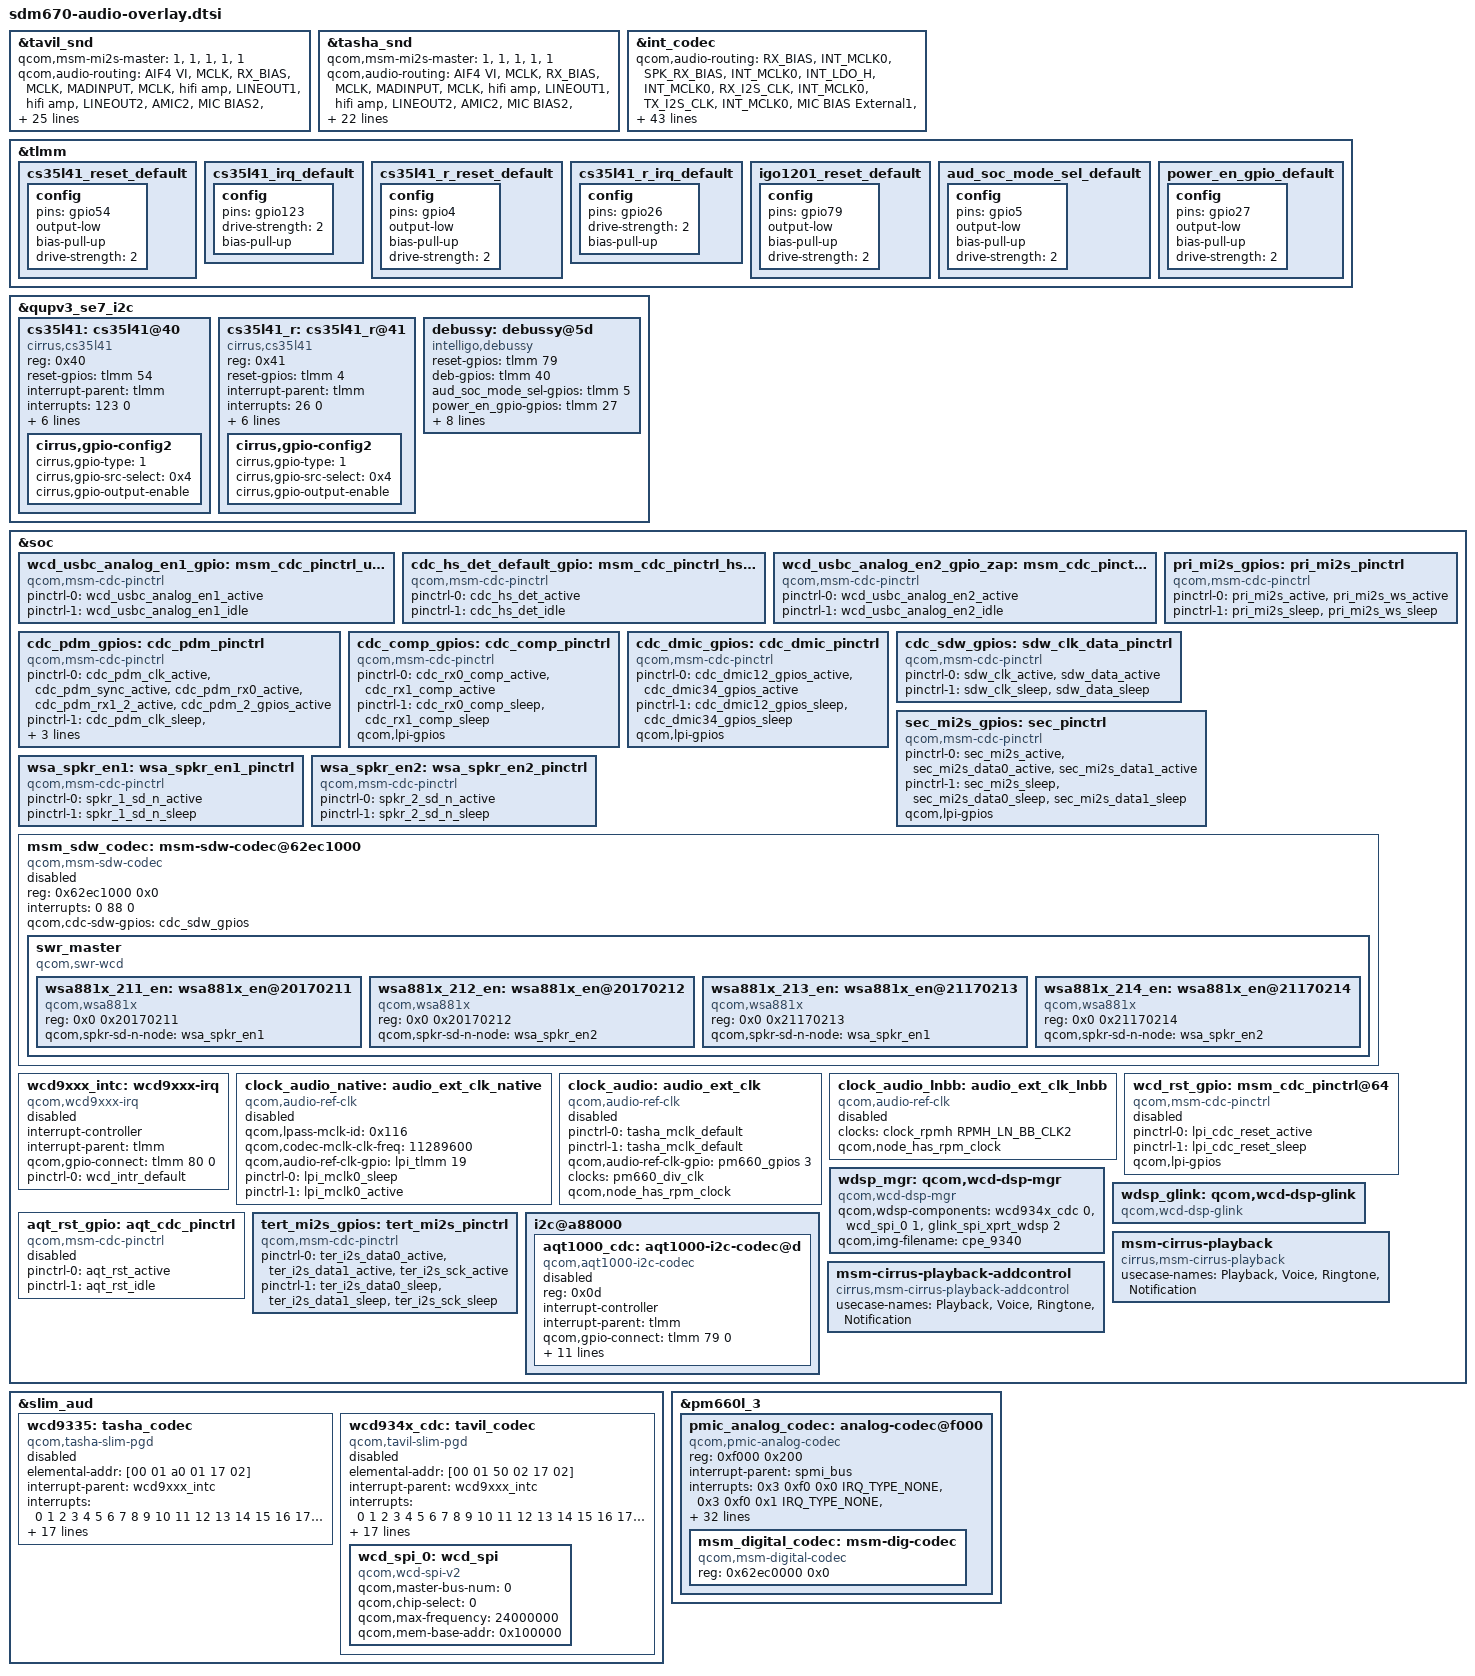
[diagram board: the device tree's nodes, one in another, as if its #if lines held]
/*
 * Copyright (c) 2017-2018, The Linux Foundation. All rights reserved.
 *
 * This program is free software; you can redistribute it and/or modify
 * it under the terms of the GNU General Public License version 2 and
 * only version 2 as published by the Free Software Foundation.
 *
 * This program is distributed in the hope that it will be useful,
 * but WITHOUT ANY WARRANTY; without even the implied warranty of
 * MERCHANTABILITY or FITNESS FOR A PARTICULAR PURPOSE.  See the
 * GNU General Public License for more details.
 */
#include "sdm670-wcd.dtsi"
#include "sdm670-wsa881x.dtsi"
#include "sdm670-lpi.dtsi"
#include <dt-bindings/clock/qcom,audio-ext-clk.h>
#include <generated/autoconf.h>

&tavil_snd {
	qcom,msm-mi2s-master = <1>, <1>, <1>, <1>, <1>;
	qcom,audio-routing =
		"AIF4 VI", "MCLK",
		"RX_BIAS", "MCLK",
		"MADINPUT", "MCLK",
		"hifi amp", "LINEOUT1",
		"hifi amp", "LINEOUT2",
		"AMIC2", "MIC BIAS2",
		"MIC BIAS2", "Headset Mic",
		"AMIC3", "MIC BIAS2",
		"MIC BIAS2", "ANCRight Headset Mic",
		"AMIC4", "MIC BIAS2",
		"MIC BIAS2", "ANCLeft Headset Mic",
		"AMIC5", "MIC BIAS3",
		"MIC BIAS3", "Handset Mic",
		"DMIC0", "MIC BIAS1",
		"MIC BIAS1", "Digital Mic0",
		"DMIC1", "MIC BIAS1",
		"MIC BIAS1", "Digital Mic1",
		"DMIC2", "MIC BIAS3",
		"MIC BIAS3", "Digital Mic2",
		"DMIC3", "MIC BIAS3",
		"MIC BIAS3", "Digital Mic3",
		"DMIC4", "MIC BIAS4",
		"MIC BIAS4", "Digital Mic4",
		"DMIC5", "MIC BIAS4",
		"MIC BIAS4", "Digital Mic5",
		"SpkrLeft IN", "SPK1 OUT",
		"SpkrRight IN", "SPK2 OUT";

	qcom,msm-mbhc-hphl-swh = <1>;
	qcom,msm-mbhc-gnd-swh = <1>;
	qcom,hph-en0-gpio = <&tavil_hph_en0>;
	qcom,hph-en1-gpio = <&tavil_hph_en1>;
	qcom,msm-mclk-freq = <9600000>;
	asoc-codec = <&stub_codec>, <&ext_disp_audio_codec>;
	asoc-codec-names = "msm-stub-codec.1", "msm-ext-disp-audio-codec-rx";
	qcom,wsa-max-devs = <2>;
	qcom,wsa-devs = <&wsa881x_0211>, <&wsa881x_0212>,
		<&wsa881x_0213>, <&wsa881x_0214>;
	qcom,wsa-aux-dev-prefix = "SpkrLeft", "SpkrRight",
		"SpkrLeft", "SpkrRight";
};

&tasha_snd {
	qcom,msm-mi2s-master = <1>, <1>, <1>, <1>, <1>;
	qcom,audio-routing =
		"AIF4 VI", "MCLK",
		"RX_BIAS", "MCLK",
		"MADINPUT", "MCLK",
		"hifi amp", "LINEOUT1",
		"hifi amp", "LINEOUT2",
		"AMIC2", "MIC BIAS2",
		"MIC BIAS2", "Headset Mic",
		"AMIC3", "MIC BIAS2",
		"MIC BIAS2", "ANCRight Headset Mic",
		"AMIC4", "MIC BIAS2",
		"MIC BIAS2", "ANCLeft Headset Mic",
		"AMIC5", "MIC BIAS3",
		"MIC BIAS3", "Handset Mic",
		"DMIC0", "MIC BIAS1",
		"MIC BIAS1", "Digital Mic0",
		"DMIC1", "MIC BIAS1",
		"MIC BIAS1", "Digital Mic1",
		"DMIC2", "MIC BIAS3",
		"MIC BIAS3", "Digital Mic2",
		"DMIC3", "MIC BIAS3",
		"MIC BIAS3", "Digital Mic3",
		"DMIC4", "MIC BIAS4",
		"MIC BIAS4", "Digital Mic4",
		"DMIC5", "MIC BIAS4",
		"MIC BIAS4", "Digital Mic5",
		"SpkrLeft IN", "SPK1 OUT",
		"SpkrRight IN", "SPK2 OUT";

	qcom,msm-mbhc-hphl-swh = <0>;
	qcom,msm-mbhc-gnd-swh = <0>;
	qcom,msm-mclk-freq = <9600000>;
	asoc-codec = <&stub_codec>;
	asoc-codec-names = "msm-stub-codec.1";
	qcom,wsa-max-devs = <2>;
	qcom,wsa-devs = <&wsa881x_211>, <&wsa881x_212>,
		<&wsa881x_213>, <&wsa881x_214>;
	qcom,wsa-aux-dev-prefix = "SpkrLeft", "SpkrRight",
		"SpkrLeft", "SpkrRight";
};

&int_codec {
	qcom,audio-routing =
		"RX_BIAS", "INT_MCLK0",
		"SPK_RX_BIAS", "INT_MCLK0",
		"INT_LDO_H", "INT_MCLK0",
		"RX_I2S_CLK", "INT_MCLK0",
		"TX_I2S_CLK", "INT_MCLK0",
#if defined(CONFIG_PRODUCT_ZAP)
		"MIC BIAS External1", "Handset Mic",
		"MIC BIAS External2", "Headset Mic",
		"MIC BIAS External3", "Secondary Mic",
		"AMIC1", "MIC BIAS External",
		"AMIC2", "MIC BIAS External2",
		"AMIC3", "MIC BIAS External3",
#else
		"MIC BIAS External", "Handset Mic",
		"MIC BIAS External2", "Headset Mic",
		"MIC BIAS External", "Secondary Mic",
		"AMIC1", "MIC BIAS External",
		"AMIC2", "MIC BIAS External2",
		"AMIC3", "MIC BIAS External",
		"DMIC1", "MIC BIAS External",
		"MIC BIAS External", "Digital Mic1",
		"DMIC2", "MIC BIAS External",
		"MIC BIAS External", "Digital Mic2",
		"DMIC3", "MIC BIAS External",
		"MIC BIAS External", "Digital Mic3",
		"DMIC4", "MIC BIAS External",
		"MIC BIAS External", "Digital Mic4",
		"MICBIAS_REGULATOR", "VDDA18_L10_REGULATOR",
		"VDDA18_L10_REGULATOR", "VDD_L1_REGULATOR",
#endif
		"SpkrLeft IN", "SPK1 OUT",
		"SpkrRight IN", "SPK2 OUT",
		"PDM_IN_RX1", "PDM_OUT_RX1",
		"PDM_IN_RX2", "PDM_OUT_RX2",
		"PDM_IN_RX3", "PDM_OUT_RX3",
		"ADC1_IN", "ADC1_OUT",
		"ADC2_IN", "ADC2_OUT",
		"ADC3_IN", "ADC3_OUT";
	qcom,msm-mi2s-master = <1>, <1>, <1>, <1>, <1>;
	qcom,msm-mclk-freq = <9600000>;
	qcom,msm-mbhc-hphl-swh = <1>;
	qcom,msm-mbhc-gnd-swh = <1>;
	qcom,msm-micbias2-ext-cap;
#if defined(CONFIG_PRODUCT_KUNLUN2)
        qcom,msm-micbias1-ext-cap;
#endif
	qcom,msm-hs-micbias-type = "external";
	/* huaqin add for JD2019-123 by xudayi at 2018/08/3 start */
      //qcom,sec-mi2s-gpios = <&sec_mi2s_gpios>;
	/* huaqin add for JD2019-123 by xudayi at 2018/08/3 end */

#if defined(CONFIG_PRODUCT_ZAP)
	qcom,msm-mbhc-usbc-audio-supported = <1>;
	qcom,usbc-analog-force_detect_gpio = <&cdc_hs_det_default_gpio>;
	qcom,usbc-analog-en1-gpio = <&wcd_usbc_analog_en1_gpio>;
	qcom,usbc-analog-en2-gpio = <&wcd_usbc_analog_en2_gpio_zap>;
	/*qcom,usbc-analog-en2-gpio = <&tlmm 50 0>;
	pinctrl-names = "aud_active", "aud_sleep";
	pinctrl-0 = <&wcd_usbc_analog_en2_active>;
	pinctrl-1 = <&wcd_usbc_analog_en2_idle>;*/
#endif

	qcom,cdc-pdm-gpios = <&cdc_pdm_gpios>;
	qcom,cdc-comp-gpios = <&cdc_comp_gpios>;
	qcom,cdc-dmic-gpios = <&cdc_dmic_gpios>;
#if defined(CONFIG_PRODUCT_ZAP)
	qcom,pri-mi2s-gpios = <&pri_mi2s_gpios>;
	qcom,sec-mi2s-gpios = <&sec_mi2s_gpios>;
	qcom,tert-mi2s-gpios = <&tert_mi2s_gpios>;
#endif

	asoc-codec = <&stub_codec>, <&msm_digital_codec>,
		     <&pmic_analog_codec>, <&msm_sdw_codec>,
		     /* huaqin add for JD2019-123 by xudayi at 2018/08/31 start */
		     <&ext_disp_audio_codec>,
#if defined(CONFIG_PRODUCT_ZAP)
		     <&cs35l41>, <&cs35l41_r>, <&debussy>;
#else
		     <&cs35l41>, <&cs35l41_r>;
#endif
		     /* huaqin add for JD2019-123 by xudayi at 2018/08/31 end */
	asoc-codec-names = "msm-stub-codec.1", "msm-dig-codec",
			   "analog-codec", "msm_sdw_codec",
			   /* huaqin add for JD2019-123 by xudayi at 2018/08/31 start */
			   "msm-ext-disp-audio-codec-rx",
#if defined(CONFIG_PRODUCT_ZAP)
		     "cs35l41", "cs35l41_r", "debussy";
#else
			   "cs35l41", "cs35l41_r";
#endif
			   /* huaqin add for JD2019-123 by xudayi at 2018/08/31 end */
	/* huaqin add for JD2019-111 by xudayi at 2018/08/30 start */
	qcom,wsa-disable;
	qcom,wsa-max-devs = <0>;
	/* huaqin add for JD2019-111 by xudayi at 2018/08/30 end */
	qcom,wsa-devs = <&wsa881x_211_en>, <&wsa881x_212_en>,
			<&wsa881x_213_en>, <&wsa881x_214_en>;
	qcom,wsa-aux-dev-prefix = "SpkrLeft", "SpkrRight",
				  "SpkrLeft", "SpkrRight";
};


/* huaqin add for JD2019-123 by xudayi at 2018/08/31 start */
&tlmm {
	cs35l41_reset_default: cs35l41_reset_default {
		config {
#if defined(CONFIG_PRODUCT_ZAP)
			pins = "gpio54";
#else
			pins = "gpio93";
#endif
			output-low;
			bias-pull-up;
			drive-strength = <2>;
		};
	};

	/* huaqin add for JD2019-303 by xudayi at 2018/09/12 start */
	cs35l41_irq_default: cs35l41_irq_default {
		config {
#if defined(CONFIG_PRODUCT_ZAP)
			pins = "gpio123";
#else
			pins = "gpio26";
#endif
			drive-strength = <2>;
			bias-pull-up;
		};
	};
	/* huaqin add for JD2019-303 by xudayi at 2018/09/12 end */

	cs35l41_r_reset_default: cs35l41_r_reset_default {
		config {
#if defined(CONFIG_PRODUCT_ZAP)
			pins = "gpio4";
#else
			pins = "gpio50";
#endif
			output-low;
			bias-pull-up;
			drive-strength = <2>;
		};
	};
	/* huaqin add for JD2019-303 by xudayi at 2018/09/12 start */
	cs35l41_r_irq_default: cs35l41_r_irq_default {
		config {
#if defined(CONFIG_PRODUCT_ZAP)
			pins = "gpio26";
#else
			pins = "gpio49";
#endif
			drive-strength = <2>;
			bias-pull-up;
		};
	};
	/* huaqin add for JD2019-303 by xudayi at 2018/09/12 end */
#if defined(CONFIG_PRODUCT_ZAP)
	igo1201_reset_default: igo1201_reset_default {
		config {
			pins = "gpio79";
			output-low;
			bias-pull-up;
			drive-strength = <2>;
		};
	};

	aud_soc_mode_sel_default: aud_soc_mode_sel_default {
		config {
			pins = "gpio5";
			output-low;
			bias-pull-up;
			drive-strength = <2>;
		};
	};

	power_en_gpio_default: power_en_gpio_default {
		config {
			pins = "gpio27";
			output-low;
			bias-pull-up;
			drive-strength = <2>;
		};
	};
#endif
};

#if defined(CONFIG_PRODUCT_ZAP)
&qupv3_se7_i2c {
        status = "okay";

	/* Speaker Amp */
	cs35l41:cs35l41@40 {
		status = "okay";
		compatible = "cirrus,cs35l41";
		reg = <0x40>;

		reset-gpios = <&tlmm 54 0>;
		interrupt-parent = <&tlmm>;
		interrupts = <123 0>;
		interrupt-names = "amp_l_irq";

		cirrus,right-channel-amp; /* Set Speaker Amp as default Right channel */
		cirrus,boost-peak-milliamp = <4500>;
		cirrus,boost-ind-nanohenry = <1000>;
		cirrus,boost-cap-microfarad = <15>;
		cirrus,asp-sdout-hiz = <0x3>;

		pinctrl-names = "reset";
		pinctrl-0 = <&cs35l41_reset_default>;
		cirrus,gpio-config2 {
			cirrus,gpio-type = <1>; /* 0 indicate gpio, 1 indicate interrupt */
			cirrus,gpio-src-select = <0x4>;
			cirrus,gpio-output-enable;
		};
 	};

	/* Receiver Amp */
	cs35l41_r:cs35l41_r@41 {
		status = "okay";
		compatible = "cirrus,cs35l41";
		reg = <0x41>;

		reset-gpios = <&tlmm 4 0>;
		interrupt-parent = <&tlmm>;
		interrupts = <26 0>;
		interrupt-names = "amp_r_irq";

		cirrus,boost-peak-milliamp = <4500>;
		cirrus,boost-ind-nanohenry = <1000>;
		cirrus,boost-cap-microfarad = <15>;
		cirrus,asp-sdout-hiz = <0x3>;
		cirrus,dsp-recovery;
		pinctrl-names = "reset";
		pinctrl-0 = <&cs35l41_r_reset_default>;
		cirrus,gpio-config2 {
			cirrus,gpio-type = <1>; /* 0 indicate gpio, 1 indicate interrupt */
			cirrus,gpio-src-select = <0x4>;
			cirrus,gpio-output-enable;
		};
	};

	debussy:debussy@5d {
			status = "okay";
			compatible = "intelligo,debussy";
			reset-gpios = <&tlmm 79 0>;
			deb-gpios = <&tlmm 40 0>;
			aud_soc_mode_sel-gpios = <&tlmm 5 0>;
			power_en_gpio-gpios = <&tlmm 27 0>;
			reg = <0x5d>;
			interrupt-parent = <&tlmm>;
			interrupts = <40 IRQ_TYPE_EDGE_RISING>;
			debounce = <5>;
			clock-names = "igo_mclk";
			clocks = <&clock_rpmh RPMH_LN_BB_CLK2>;

			pinctrl-names = "reset", "aud_soc_mode_sel", "power_en_gpio";
			pinctrl-0 = <&igo1201_reset_default>;
			pinctrl-1 = <&aud_soc_mode_sel_default>;
			pinctrl-2 = <&power_en_gpio_default>;
	};
};
#else
&qupv3_se3_i2c {
        status = "okay";

	/* Speaker Amp */
	cs35l41:cs35l41@43 {
		status = "okay";
		compatible = "cirrus,cs35l41";
		reg = <0x43>;

		reset-gpios = <&tlmm 93 0>;
		interrupt-parent = <&tlmm>;
		interrupts = <26 0>;
		interrupt-names = "amp_l_irq";

		cirrus,right-channel-amp; /* Set Speaker Amp as default Right channel */
		cirrus,boost-peak-milliamp = <4500>;
		cirrus,boost-ind-nanohenry = <1000>;
		cirrus,boost-cap-microfarad = <15>;
		cirrus,asp-sdout-hiz = <0x3>;

		pinctrl-names = "reset";
		pinctrl-0 = <&cs35l41_reset_default>;
		cirrus,gpio-config2 {
			cirrus,gpio-type = <1>; /* 0 indicate gpio, 1 indicate interrupt */
			cirrus,gpio-src-select = <0x4>;
			cirrus,gpio-output-enable;
		};
	};

	/* Receiver Amp */
	cs35l41_r:cs35l41_r@40 {
		status = "okay";
		compatible = "cirrus,cs35l41";
		reg = <0x40>;

		reset-gpios = <&tlmm 50 0>;
		interrupt-parent = <&tlmm>;
		interrupts = <49 0>;
		interrupt-names = "amp_r_irq";

		cirrus,boost-peak-milliamp = <4500>;
		cirrus,boost-ind-nanohenry = <1000>;
		cirrus,boost-cap-microfarad = <15>;
		cirrus,asp-sdout-hiz = <0x3>;

		pinctrl-names = "reset";
		pinctrl-0 = <&cs35l41_r_reset_default>;
		cirrus,gpio-config2 {
			cirrus,gpio-type = <1>; /* 0 indicate gpio, 1 indicate interrupt */
			cirrus,gpio-src-select = <0x4>;
			cirrus,gpio-output-enable;
		};
	};
};
#endif

/* huaqin add for JD2019-123 by xudayi at 2018/08/31 end */
&soc {
	wcd_usbc_analog_en1_gpio: msm_cdc_pinctrl_usbc_audio_en1 {
		compatible = "qcom,msm-cdc-pinctrl";
		pinctrl-names = "aud_active", "aud_sleep";
		pinctrl-0 = <&wcd_usbc_analog_en1_active>;
		pinctrl-1 = <&wcd_usbc_analog_en1_idle>;
	};
#if defined(CONFIG_PRODUCT_ZAP)
	cdc_hs_det_default_gpio: msm_cdc_pinctrl_hs_det_default {
		compatible = "qcom,msm-cdc-pinctrl";
		pinctrl-names = "aud_active", "aud_sleep";
		pinctrl-0 = <&cdc_hs_det_active>;
		pinctrl-1 = <&cdc_hs_det_idle>;
	};

	wcd_usbc_analog_en2_gpio_zap: msm_cdc_pinctrl_usbc_audio_en2 {
		compatible = "qcom,msm-cdc-pinctrl";
		pinctrl-names = "aud_active", "aud_sleep";
		pinctrl-0 = <&wcd_usbc_analog_en2_active>;
		pinctrl-1 = <&wcd_usbc_analog_en2_idle>;
	};

	pri_mi2s_gpios: pri_mi2s_pinctrl {
		status = "ok";
		compatible = "qcom,msm-cdc-pinctrl";
		pinctrl-names = "aud_active", "aud_sleep";
		pinctrl-0 = <&pri_mi2s_active &pri_mi2s_ws_active>;
		pinctrl-1 = <&pri_mi2s_sleep &pri_mi2s_ws_sleep>;
	};
#endif
	cdc_pdm_gpios: cdc_pdm_pinctrl {
		compatible = "qcom,msm-cdc-pinctrl";
		pinctrl-names = "aud_active", "aud_sleep";
		pinctrl-0 = <&cdc_pdm_clk_active &cdc_pdm_sync_active
			     &cdc_pdm_rx0_active &cdc_pdm_rx1_2_active
			     &cdc_pdm_2_gpios_active>;
		pinctrl-1 = <&cdc_pdm_clk_sleep &cdc_pdm_sync_sleep
			     &cdc_pdm_rx0_sleep &cdc_pdm_rx1_2_sleep
			     &cdc_pdm_2_gpios_sleep>;
		qcom,lpi-gpios;
	};

	cdc_comp_gpios: cdc_comp_pinctrl {
		compatible = "qcom,msm-cdc-pinctrl";
		pinctrl-names = "aud_active", "aud_sleep";
		pinctrl-0 = <&cdc_rx0_comp_active &cdc_rx1_comp_active>;
		pinctrl-1 = <&cdc_rx0_comp_sleep &cdc_rx1_comp_sleep>;
		qcom,lpi-gpios;
	};

	cdc_dmic_gpios: cdc_dmic_pinctrl {
		compatible = "qcom,msm-cdc-pinctrl";
		pinctrl-names = "aud_active", "aud_sleep";
		pinctrl-0 = <&cdc_dmic12_gpios_active
			     &cdc_dmic34_gpios_active>;
		pinctrl-1 = <&cdc_dmic12_gpios_sleep
			     &cdc_dmic34_gpios_sleep>;
		qcom,lpi-gpios;
	};

	cdc_sdw_gpios: sdw_clk_data_pinctrl {
		compatible = "qcom,msm-cdc-pinctrl";
#ifdef CONFIG_PRODUCT_JD2019
		pinctrl-names = "aud_active", "aud_sleep";
		pinctrl-0 = <&sdw_clk_active &sdw_data_active>;
		pinctrl-1 = <&sdw_clk_sleep &sdw_data_sleep>;
#endif
	};

	/* huaqin add for JD2019-123 by xudayi at 2018/08/3 start */
	sec_mi2s_gpios: sec_pinctrl {
		compatible = "qcom,msm-cdc-pinctrl";
		pinctrl-names = "aud_active", "aud_sleep";
		pinctrl-0 = <&sec_mi2s_active &sec_mi2s_data0_active
			&sec_mi2s_data1_active>;
		pinctrl-1 = <&sec_mi2s_sleep &sec_mi2s_data0_sleep
			&sec_mi2s_data1_sleep>;
		qcom,lpi-gpios;
	};
	/* huaqin add for JD2019-123 by xudayi at 2018/08/3 end */

	wsa_spkr_en1: wsa_spkr_en1_pinctrl {
		compatible = "qcom,msm-cdc-pinctrl";
#ifdef CONFIG_PRODUCT_JD2019
		pinctrl-names = "aud_active", "aud_sleep";
		pinctrl-0 = <&spkr_1_sd_n_active>;
		pinctrl-1 = <&spkr_1_sd_n_sleep>;
#endif
	};

	wsa_spkr_en2: wsa_spkr_en2_pinctrl {
		compatible = "qcom,msm-cdc-pinctrl";
#ifdef CONFIG_PRODUCT_JD2019
		pinctrl-names = "aud_active", "aud_sleep";
		pinctrl-0 = <&spkr_2_sd_n_active>;
		pinctrl-1 = <&spkr_2_sd_n_sleep>;
#endif
	};

	msm_sdw_codec: msm-sdw-codec@62ec1000 {
		status = "disabled";
		compatible = "qcom,msm-sdw-codec";
		reg = <0x62ec1000 0x0>;
		interrupts = <0 88 0>;
		interrupt-names = "swr_master_irq";
		qcom,cdc-sdw-gpios = <&cdc_sdw_gpios>;

		swr_master {
			compatible = "qcom,swr-wcd";
			#address-cells = <2>;
			#size-cells = <0>;

			wsa881x_211_en: wsa881x_en@20170211 {
				compatible = "qcom,wsa881x";
				reg = <0x0 0x20170211>;
				qcom,spkr-sd-n-node = <&wsa_spkr_en1>;
			};

			wsa881x_212_en: wsa881x_en@20170212 {
				compatible = "qcom,wsa881x";
				reg = <0x0 0x20170212>;
				qcom,spkr-sd-n-node = <&wsa_spkr_en2>;
			};

			wsa881x_213_en: wsa881x_en@21170213 {
				compatible = "qcom,wsa881x";
				reg = <0x0 0x21170213>;
				qcom,spkr-sd-n-node = <&wsa_spkr_en1>;
			};

			wsa881x_214_en: wsa881x_en@21170214 {
				compatible = "qcom,wsa881x";
				reg = <0x0 0x21170214>;
				qcom,spkr-sd-n-node = <&wsa_spkr_en2>;
			};
		};
	};

	wcd9xxx_intc: wcd9xxx-irq {
		status = "disabled";
		compatible = "qcom,wcd9xxx-irq";
		interrupt-controller;
		#interrupt-cells = <1>;
		interrupt-parent = <&tlmm>;
		qcom,gpio-connect = <&tlmm 80 0>;
		pinctrl-names = "default";
		pinctrl-0 = <&wcd_intr_default>;
	};

	clock_audio_native: audio_ext_clk_native {
		status = "disabled";
		compatible = "qcom,audio-ref-clk";
		#clock-cells = <1>;
		qcom,lpass-mclk-id = <0x116>;
		qcom,codec-mclk-clk-freq = <11289600>;
		qcom,audio-ref-clk-gpio = <&lpi_tlmm 19 0>;
		pinctrl-names = "sleep", "active";
		pinctrl-0 = <&lpi_mclk0_sleep>;
		pinctrl-1 = <&lpi_mclk0_active>;
	};

	clock_audio: audio_ext_clk {
		status = "disabled";
		compatible = "qcom,audio-ref-clk";
		pinctrl-names = "active", "sleep";
		pinctrl-0 = <&tasha_mclk_default>;
		pinctrl-1 = <&tasha_mclk_default>;
		qcom,audio-ref-clk-gpio = <&pm660_gpios 3 0>;
		clock-names = "osr_clk";
		clocks = <&pm660_div_clk>;
		qcom,node_has_rpm_clock;
		#clock-cells = <1>;
	};

	clock_audio_lnbb: audio_ext_clk_lnbb {
		status = "disabled";
		compatible = "qcom,audio-ref-clk";
		clock-names = "osr_clk";
		clocks = <&clock_rpmh RPMH_LN_BB_CLK2>;
		qcom,node_has_rpm_clock;
		#clock-cells = <1>;
	};

	wcd_rst_gpio: msm_cdc_pinctrl@64 {
		status = "disabled";
		compatible = "qcom,msm-cdc-pinctrl";
		pinctrl-names = "aud_active", "aud_sleep";
		pinctrl-0 = <&lpi_cdc_reset_active>;
		pinctrl-1 = <&lpi_cdc_reset_sleep>;
		qcom,lpi-gpios;
	};

	wdsp_mgr: qcom,wcd-dsp-mgr {
		compatible = "qcom,wcd-dsp-mgr";
		qcom,wdsp-components = <&wcd934x_cdc 0>,
				       <&wcd_spi_0 1>,
				       <&glink_spi_xprt_wdsp 2>;
					qcom,img-filename = "cpe_9340";
	};

	wdsp_glink: qcom,wcd-dsp-glink {
		compatible = "qcom,wcd-dsp-glink";
	};

	aqt_rst_gpio: aqt_cdc_pinctrl {
		status = "disabled";
		compatible = "qcom,msm-cdc-pinctrl";
		pinctrl-names = "aud_active", "aud_sleep";
		pinctrl-0 = <&aqt_rst_active>;
		pinctrl-1 = <&aqt_rst_idle>;
	};

	tert_mi2s_gpios: tert_mi2s_pinctrl {
#if defined(CONFIG_PRODUCT_ZAP)
		status = "okay";
#else
		status = "disabled";
#endif
		compatible = "qcom,msm-cdc-pinctrl";
		pinctrl-names = "aud_active", "aud_sleep";
		pinctrl-0 = <&ter_i2s_data0_active &ter_i2s_data1_active
			     &ter_i2s_sck_active>;
		pinctrl-1 = <&ter_i2s_data0_sleep &ter_i2s_data1_sleep
			     &ter_i2s_sck_sleep>;
	};

	i2c@a88000 {
		aqt1000_cdc: aqt1000-i2c-codec@d {
			status = "disabled";
			compatible = "qcom,aqt1000-i2c-codec";
			reg = <0x0d>;

			interrupt-controller;
			#interrupt-cells = <1>;
			interrupt-parent = <&tlmm>;
			qcom,gpio-connect = <&tlmm 79 0>;
			pinctrl-names = "default";
			pinctrl-0 = <&aqt_intr_default>;

			qcom,aqt-rst-gpio-node = <&aqt_rst_gpio>;

			qcom,cdc-vdd-mic-bias-supply = <&pm660l_bob>;
			qcom,cdc-vdd-mic-bias-voltage = <3312000 3312000>;
			qcom,cdc-vdd-mic-bias-current = <30400>;

			qcom,cdc-static-supplies = "cdc-vdd-mic-bias";

			qcom,cdc-micbias-ldoh-v = <3>;

			qcom,cdc-ext-clk-rate = <19200000>;
			qcom,cdc-mclk-clk-rate = <9600000>;

			qcom,cdc-micbias1-mv = <1800>;

			clock-names = "aqt_clk";
			clocks = <&clock_audio_lnbb AUDIO_PMIC_LNBB_CLK>;
		};
	};
	msm-cirrus-playback {
		compatible = "cirrus,msm-cirrus-playback";
		usecase-names = "Playback", "Voice", "Ringtone", "Notification";
	};

	msm-cirrus-playback-addcontrol {
		compatible = "cirrus,msm-cirrus-playback-addcontrol";
		usecase-names = "Playback", "Voice", "Ringtone", "Notification";
	};
};

&slim_aud {
	wcd9335: tasha_codec {
		status = "disabled";
		compatible = "qcom,tasha-slim-pgd";
		elemental-addr = [00 01 a0 01 17 02];

		interrupt-parent = <&wcd9xxx_intc>;
		interrupts = <0 1 2 3 4 5 6 7 8 9 10 11 12 13 14 15 16
		      17 18 19 20 21 22 23 24 25 26 27 28 29
		      30>;

		qcom,wcd-rst-gpio-node = <&wcd_rst_gpio>;

		clock-names = "wcd_clk", "wcd_native_clk";
		clocks = <&clock_audio AUDIO_PMI_CLK>,
			 <&clock_audio_native AUDIO_LPASS_MCLK>;

		cdc-vdd-mic-bias-supply = <&pm660l_bob>;
		qcom,cdc-vdd-mic-bias-voltage = <3312000 3312000>;
		qcom,cdc-vdd-mic-bias-current = <30400>;

		qcom,cdc-static-supplies = "cdc-vdd-mic-bias";

		qcom,cdc-micbias1-mv = <1800>;
		qcom,cdc-micbias2-mv = <1800>;
		qcom,cdc-micbias3-mv = <1800>;
		qcom,cdc-micbias4-mv = <1800>;

		qcom,cdc-mclk-clk-rate = <9600000>;
		qcom,cdc-slim-ifd = "tasha-slim-ifd";
		qcom,cdc-slim-ifd-elemental-addr = [00 00 a0 01 17 02];
		qcom,cdc-dmic-sample-rate = <4800000>;
		qcom,cdc-mad-dmic-rate = <600000>;
	};

	wcd934x_cdc: tavil_codec {
		status = "disabled";
		compatible = "qcom,tavil-slim-pgd";
		elemental-addr = [00 01 50 02 17 02];

		interrupt-parent = <&wcd9xxx_intc>;
		interrupts = <0 1 2 3 4 5 6 7 8 9 10 11 12 13 14 15 16
			      17 18 19 20 21 22 23 24 25 26 27 28 29
			      30 31>;

		qcom,wcd-rst-gpio-node = <&wcd_rst_gpio>;

		clock-names = "wcd_clk";
		clocks = <&clock_audio_lnbb AUDIO_PMIC_LNBB_CLK>;

		cdc-vdd-mic-bias-supply = <&pm660l_bob>;
		qcom,cdc-vdd-mic-bias-voltage = <3312000 3312000>;
		qcom,cdc-vdd-mic-bias-current = <30400>;

		qcom,cdc-static-supplies = "cdc-vdd-mic-bias";

		qcom,cdc-micbias1-mv = <1800>;
		qcom,cdc-micbias2-mv = <1800>;
		qcom,cdc-micbias3-mv = <1800>;
		qcom,cdc-micbias4-mv = <1800>;

		qcom,cdc-mclk-clk-rate = <9600000>;
		qcom,cdc-slim-ifd = "tavil-slim-ifd";
		qcom,cdc-slim-ifd-elemental-addr = [00 00 50 02 17 02];
		qcom,cdc-dmic-sample-rate = <4800000>;
		qcom,cdc-mad-dmic-rate = <600000>;

		qcom,wdsp-cmpnt-dev-name = "tavil_codec";

		wcd_spi_0: wcd_spi {
			compatible = "qcom,wcd-spi-v2";
			qcom,master-bus-num = <0>;
			qcom,chip-select = <0>;
			qcom,max-frequency = <24000000>;
			qcom,mem-base-addr = <0x100000>;
		};
	};
};

&pm660l_3 {
	pmic_analog_codec: analog-codec@f000 {
		status = "okay";
		compatible = "qcom,pmic-analog-codec";
		reg = <0xf000 0x200>;
		#address-cells = <2>;
		#size-cells = <0>;
		interrupt-parent = <&spmi_bus>;
		interrupts = <0x3 0xf0 0x0 IRQ_TYPE_NONE>,
			     <0x3 0xf0 0x1 IRQ_TYPE_NONE>,
			     <0x3 0xf0 0x2 IRQ_TYPE_NONE>,
			     <0x3 0xf0 0x3 IRQ_TYPE_NONE>,
			     <0x3 0xf0 0x4 IRQ_TYPE_NONE>,
			     <0x3 0xf0 0x5 IRQ_TYPE_NONE>,
			     <0x3 0xf0 0x6 IRQ_TYPE_NONE>,
			     <0x3 0xf0 0x7 IRQ_TYPE_NONE>,
			     <0x3 0xf1 0x0 IRQ_TYPE_NONE>,
			     <0x3 0xf1 0x1 IRQ_TYPE_NONE>,
			     <0x3 0xf1 0x2 IRQ_TYPE_NONE>,
			     <0x3 0xf1 0x3 IRQ_TYPE_NONE>,
			     <0x3 0xf1 0x4 IRQ_TYPE_NONE>,
			     <0x3 0xf1 0x5 IRQ_TYPE_NONE>;
		interrupt-names = "spk_cnp_int",
				   "spk_clip_int",
				   "spk_ocp_int",
				   "ins_rem_det1",
				   "but_rel_det",
				   "but_press_det",
				   "ins_rem_det",
				   "mbhc_int",
				   "ear_ocp_int",
				   "hphr_ocp_int",
				   "hphl_ocp_det",
				   "ear_cnp_int",
				   "hphr_cnp_int",
				   "hphl_cnp_int";

		cdc-vdda-cp-supply = <&pm660_s4>;
		qcom,cdc-vdda-cp-voltage = <1900000 2050000>;
		qcom,cdc-vdda-cp-current = <50000>;

		cdc-vdd-pa-supply = <&pm660_s4>;
		qcom,cdc-vdd-pa-voltage = <2040000 2040000>;
		qcom,cdc-vdd-pa-current = <260000>;

		cdc-vdd-mic-bias-supply = <&pm660l_l7>;
		qcom,cdc-vdd-mic-bias-voltage = <3088000 3088000>;
		qcom,cdc-vdd-mic-bias-current = <5000>;

		cdc-vdda18-l10-supply = <&pm660_l10>;
		qcom,cdc-vdda18-l10-voltage = <1800000 1800000>;
		qcom,cdc-vdda18-l10-current = <30000>;

		cdc-vdd-l1-supply = <&pm660l_l1>;
		qcom,cdc-vdd-l1-voltage = <880000 880000>;
		qcom,cdc-vdd-l1-current = <30000>;

		qcom,cdc-mclk-clk-rate = <9600000>;

		qcom,cdc-static-supplies = "cdc-vdda-cp",
					   "cdc-vdd-pa";

		qcom,cdc-on-demand-supplies = "cdc-vdd-mic-bias",
					      "cdc-vdda18-l10",
					      "cdc-vdd-l1";

		/*
		 * Not marking address @ as driver searches this child
		 * with name msm-dig-codec
		 */
		msm_digital_codec: msm-dig-codec {
			compatible = "qcom,msm-digital-codec";
			reg = <0x62ec0000 0x0>;
		};
	};
};
